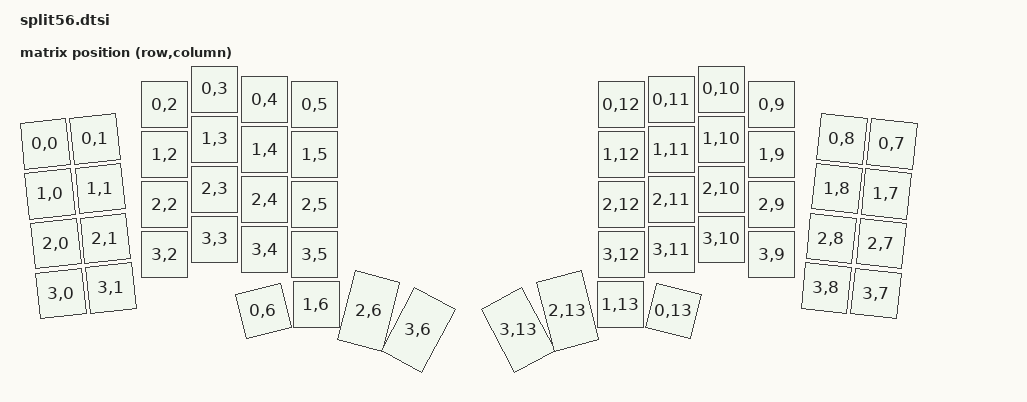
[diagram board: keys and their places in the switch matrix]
/* Generated by tools/zmk_generate.py from pcb/pins.yaml and layout/generated/. Do not edit. */

/*
 * The matrix transform and physical layout, the same in all three parts.
 * Matrix: 4 rows by 7 columns a half (C0, C1, C2, C3, C4, C5, T); the right half is offset by 7 columns.
 * Key order: each finger row from the left outer pinky to the right outer pinky, then the
 * thumbs, left T0..T3 and right T3..T0.
 */

#include <dt-bindings/zmk/matrix_transform.h>
#include <physical_layouts.dtsi>

/ {
    chosen {
        zmk,physical-layout = &physical_layout0;
    };

    default_transform: keymap_transform_0 {
        compatible = "zmk,matrix-transform";
        columns = <14>;
        rows = <4>;
        map = <
RC(0,0)    RC(0,1)    RC(0,2)    RC(0,3)    RC(0,4)    RC(0,5)    RC(0,12)   RC(0,11)   RC(0,10)   RC(0,9)    RC(0,8)    RC(0,7)
RC(1,0)    RC(1,1)    RC(1,2)    RC(1,3)    RC(1,4)    RC(1,5)    RC(1,12)   RC(1,11)   RC(1,10)   RC(1,9)    RC(1,8)    RC(1,7)
RC(2,0)    RC(2,1)    RC(2,2)    RC(2,3)    RC(2,4)    RC(2,5)    RC(2,12)   RC(2,11)   RC(2,10)   RC(2,9)    RC(2,8)    RC(2,7)
RC(3,0)    RC(3,1)    RC(3,2)    RC(3,3)    RC(3,4)    RC(3,5)    RC(3,12)   RC(3,11)   RC(3,10)   RC(3,9)    RC(3,8)    RC(3,7)
RC(0,6)    RC(1,6)    RC(2,6)    RC(3,6)    RC(3,13)   RC(2,13)   RC(1,13)   RC(0,13)
        >;
    };

    physical_layout0: physical_layout_0 {
        compatible = "zmk,physical-layout";
        display-name = "Default";
        transform = <&default_transform>;
        keys  //                 w   h    x    y     rot   rx   ry
            = <&key_physical_attrs 100 100   50  160  (-600)  100  210>  // L C0R1
            , <&key_physical_attrs 100 100  149  150  (-600)  199  200>  // L C1R1
            , <&key_physical_attrs 100 100  289   81       0  339  131>  // L C2R1
            , <&key_physical_attrs 100 100  389   50       0  439  100>  // L C3R1
            , <&key_physical_attrs 100 100  489   71       0  539  121>  // L C4R1
            , <&key_physical_attrs 100 100  589   81       0  639  131>  // L C5R1
            , <&key_physical_attrs 100 100 1203   81       0 1253  131>  // R C5R1
            , <&key_physical_attrs 100 100 1303   71       0 1353  121>  // R C4R1
            , <&key_physical_attrs 100 100 1403   50       0 1453  100>  // R C3R1
            , <&key_physical_attrs 100 100 1503   81       0 1553  131>  // R C2R1
            , <&key_physical_attrs 100 100 1643  150     600 1693  200>  // R C1R1
            , <&key_physical_attrs 100 100 1743  160     600 1793  210>  // R C0R1
            , <&key_physical_attrs 100 100   60  260  (-600)  110  310>  // L C0R2
            , <&key_physical_attrs 100 100  160  249  (-600)  210  299>  // L C1R2
            , <&key_physical_attrs 100 100  289  181       0  339  231>  // L C2R2
            , <&key_physical_attrs 100 100  389  150       0  439  200>  // L C3R2
            , <&key_physical_attrs 100 100  489  171       0  539  221>  // L C4R2
            , <&key_physical_attrs 100 100  589  181       0  639  231>  // L C5R2
            , <&key_physical_attrs 100 100 1203  181       0 1253  231>  // R C5R2
            , <&key_physical_attrs 100 100 1303  171       0 1353  221>  // R C4R2
            , <&key_physical_attrs 100 100 1403  150       0 1453  200>  // R C3R2
            , <&key_physical_attrs 100 100 1503  181       0 1553  231>  // R C2R2
            , <&key_physical_attrs 100 100 1633  249     600 1683  299>  // R C1R2
            , <&key_physical_attrs 100 100 1732  260     600 1782  310>  // R C0R2
            , <&key_physical_attrs 100 100   71  359  (-600)  121  409>  // L C0R3
            , <&key_physical_attrs 100 100  170  349  (-600)  220  399>  // L C1R3
            , <&key_physical_attrs 100 100  289  281       0  339  331>  // L C2R3
            , <&key_physical_attrs 100 100  389  250       0  439  300>  // L C3R3
            , <&key_physical_attrs 100 100  489  271       0  539  321>  // L C4R3
            , <&key_physical_attrs 100 100  589  281       0  639  331>  // L C5R3
            , <&key_physical_attrs 100 100 1203  281       0 1253  331>  // R C5R3
            , <&key_physical_attrs 100 100 1303  271       0 1353  321>  // R C4R3
            , <&key_physical_attrs 100 100 1403  250       0 1453  300>  // R C3R3
            , <&key_physical_attrs 100 100 1503  281       0 1553  331>  // R C2R3
            , <&key_physical_attrs 100 100 1622  349     600 1672  399>  // R C1R3
            , <&key_physical_attrs 100 100 1722  359     600 1772  409>  // R C0R3
            , <&key_physical_attrs 100 100   81  459  (-600)  131  509>  // L C0R4
            , <&key_physical_attrs 100 100  181  448  (-600)  231  498>  // L C1R4
            , <&key_physical_attrs 100 100  289  381       0  339  431>  // L C2R4
            , <&key_physical_attrs 100 100  389  350       0  439  400>  // L C3R4
            , <&key_physical_attrs 100 100  489  371       0  539  421>  // L C4R4
            , <&key_physical_attrs 100 100  589  381       0  639  431>  // L C5R4
            , <&key_physical_attrs 100 100 1203  381       0 1253  431>  // R C5R4
            , <&key_physical_attrs 100 100 1303  371       0 1353  421>  // R C4R4
            , <&key_physical_attrs 100 100 1403  350       0 1453  400>  // R C3R4
            , <&key_physical_attrs 100 100 1503  381       0 1553  431>  // R C2R4
            , <&key_physical_attrs 100 100 1612  448     600 1662  498>  // R C1R4
            , <&key_physical_attrs 100 100 1711  459     600 1761  509>  // R C0R4
            , <&key_physical_attrs 100 100  486  494 (-1400)  536  544>  // L T0
            , <&key_physical_attrs 100 100  592  481       0  642  531>  // L T1
            , <&key_physical_attrs 100 150  697  469    1400  747  544>  // L T2
            , <&key_physical_attrs 100 150  796  507    2800  846  582>  // L T3
            , <&key_physical_attrs 100 150  996  507 (-2800) 1046  582>  // R T3
            , <&key_physical_attrs 100 150 1095  469 (-1400) 1145  544>  // R T2
            , <&key_physical_attrs 100 100 1201  481       0 1251  531>  // R T1
            , <&key_physical_attrs 100 100 1306  494    1400 1356  544>  // R T0
            ;
    };
};
